# N32H7xx register map
Vendor: Nationstech Ltd.; File version: 1.0
CPU: CM7 r1p1, little endian, MPU, FPU, 4 interrupt priority bits
Registers are 32-bit, read-write, reset 0x0 unless marked. A register's access mark holds for its fields unless they carry their own. Offsets are from the block's base; [hi:lo] are bit positions; {n}, {i} and the like mark numbered series; 'fields as' and 'values as' point back to an identical list.

## RTC — Real time clock
Base 0x58005400
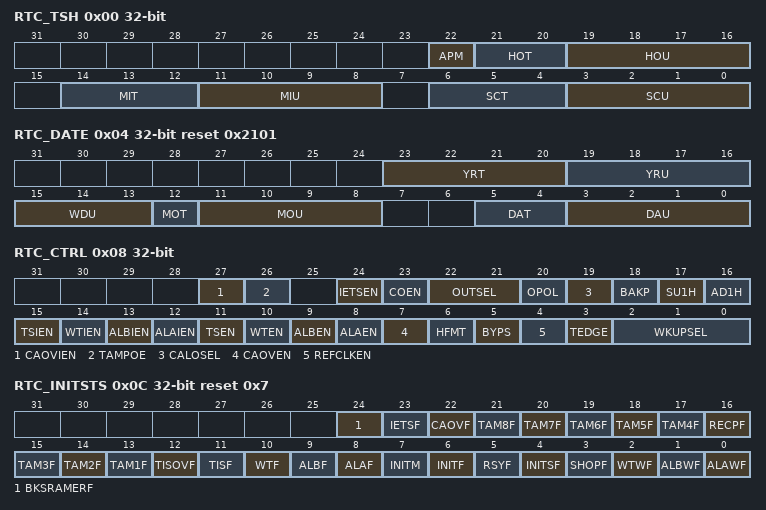
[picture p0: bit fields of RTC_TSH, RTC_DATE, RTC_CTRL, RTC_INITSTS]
0x00 RTC_TSH reset not defined
  [22] APM, [21:20] HOT, [19:16] HOU, [14:12] MIT, [11:8] MIU, [6:4] SCT, [3:0] SCU
0x04 RTC_DATE reset 0x2101
  [23:20] YRT, [19:16] YRU, [15:13] WDU, [12] MOT, [11:8] MOU, [5:4] DAT, [3:0] DAU
0x08 RTC_CTRL (reset mask 0xFFFFFF)
  [27] CAOVIEN, [26] TAMPOE, [24] IETSEN, [23] COEN, [22:21] OUTSEL, [20] OPOL, [19] CALOSEL, [18] BAKP, [17] SU1H wo, [16] AD1H wo, [15] TSIEN, [14] WTIEN, [13] ALBIEN, [12] ALAIEN, [11] TSEN, [10] WTEN, [9] ALBEN, [8] ALAEN, [7] CAOVEN, [6] HFMT, [5] BYPS, [4] REFCLKEN, [3] TEDGE, [2:0] WKUPSEL
0x0C RTC_INITSTS reset 0x7 (reset mask 0x17FFF)
  [24] BKSRAMERF ro, [23] IETSF, [22] CAOVF, [n+13] TAM{n}F (n=4..8), [16] RECPF ro, [15] TAM3F, [14] TAM2F, [13] TAM1F, [12] TISOVF, [11] TISF, [10] WTF, [9] ALBF, [8] ALAF, [7] INITM, [6] INITF ro, [5] RSYF, [4] INITSF ro, [3] SHOPF ro, [2] WTWF ro, [1] ALBWF ro, [0] ALAWF ro
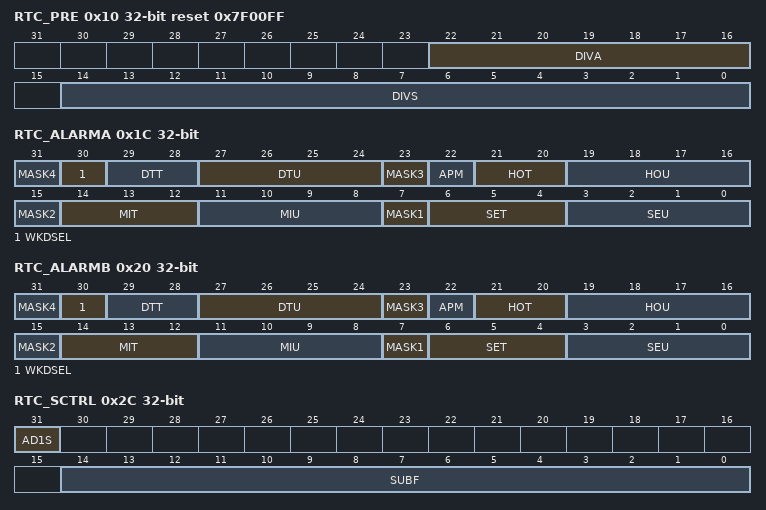
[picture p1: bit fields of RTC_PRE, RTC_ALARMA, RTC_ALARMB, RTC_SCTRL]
0x10 RTC_PRE reset 0x7F00FF
  [22:16] DIVA, [14:0] DIVS
0x14 RTC_WKUPT reset 0xFFFF
  [15:0] WKUPT
0x1C RTC_ALARMA
  [8n-1] MASK{n} (n=1..4), [30] WKDSEL, [29:28] DTT, [27:24] DTU, [22] APM, [21:20] HOT, [19:16] HOU, [14:12] MIT, [11:8] MIU, [6:4] SET, [3:0] SEU
0x20 RTC_ALARMB
  fields as RTC_ALARMA
0x24 RTC_WRP wo
  [7:0] PKEY
0x28 RTC_SUBS ro
  [15:0] SS
0x2C RTC_SCTRL wo
  [31] AD1S, [14:0] SUBF
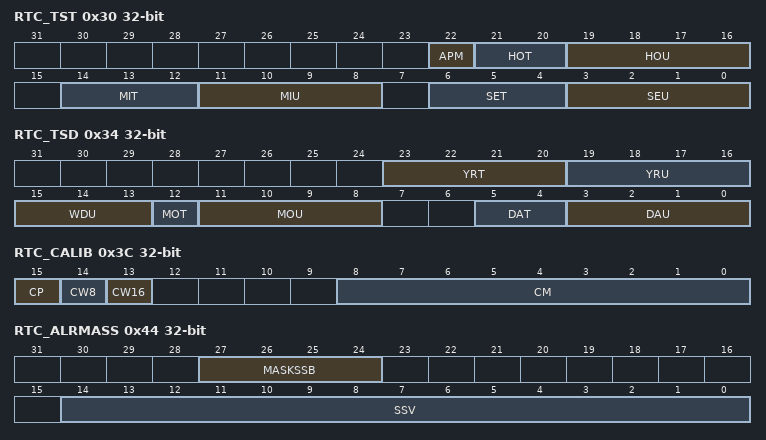
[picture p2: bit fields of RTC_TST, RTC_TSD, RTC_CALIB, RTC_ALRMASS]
0x30 RTC_TST ro (reset mask 0x7F)
  [22] APM, [21:20] HOT, [19:16] HOU, [14:12] MIT, [11:8] MIU, [6:4] SET, [3:0] SEU
0x34 RTC_TSD ro
  fields as RTC_DATE
0x38 RTC_TSSS ro
  [15:0] SSE
0x3C RTC_CALIB (reset mask 0xFF)
  [15] CP, [14] CW8, [13] CW16, [8:0] CM
0x44 RTC_ALRMASS
  [27:24] MASKSSB, [14:0] SSV
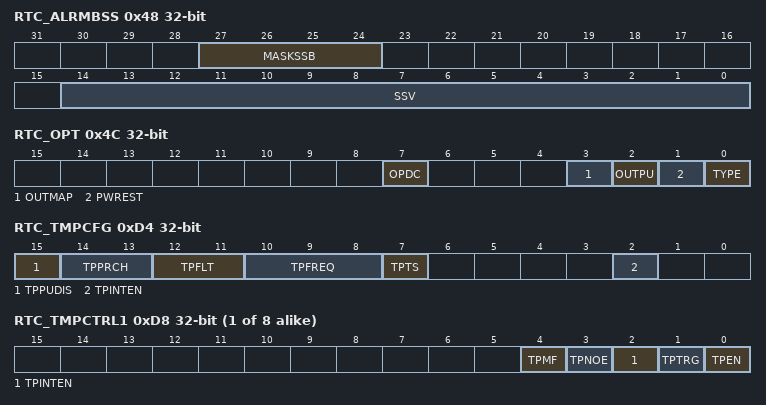
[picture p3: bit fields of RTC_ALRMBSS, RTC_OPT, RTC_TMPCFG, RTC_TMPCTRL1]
0x48 RTC_ALRMBSS
  [27:24] MASKSSB, [14:0] SSV
0x4C RTC_OPT (reset mask 0x1)
  [7] OPDC, [3] OUTMAP, [2] OUTPU, [1] PWREST, [0] TYPE
{0x4C+4i} RTC_BKP{i} (i=1..27)
  [31:0] BF
0xBC RTC_BKP28 — RTC_BKP27
  [31:0] BF
{0x4C+4i} RTC_BKP{i} (i=29..32)
  [31:0] BF
0xD4 RTC_TMPCFG
  [15] TPPUDIS, [14:13] TPPRCH, [12:11] TPFLT, [10:8] TPFREQ, [7] TPTS, [2] TPINTEN
{0xD4+4i} RTC_TMPCTRL{i} (i=1..8)
  [4] TPMF, [3] TPNOE, [2] TPINTEN, [1] TPTRG, [0] TPEN

## xSPI1 — Multi-line SPI
Base 0x51100000
Same registers: xSPI2 0x51101000
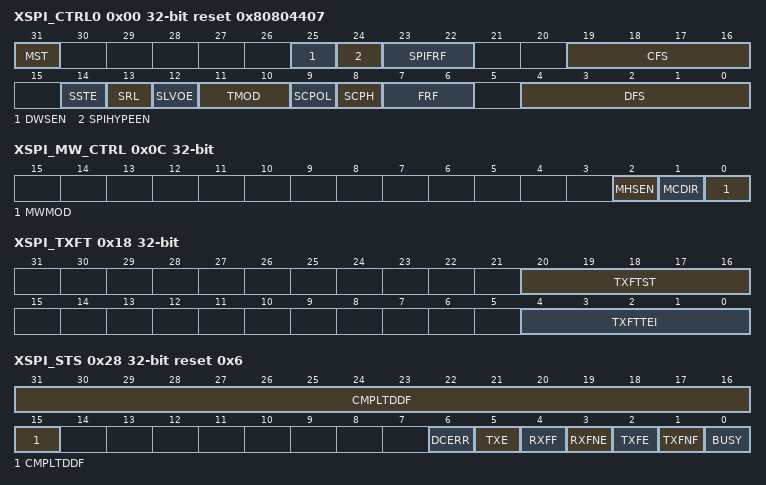
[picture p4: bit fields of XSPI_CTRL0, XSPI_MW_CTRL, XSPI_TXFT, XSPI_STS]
0x00 XSPI_CTRL0 reset 0x80804407
  [31] MST, [25] DWSEN ro, [24] SPIHYPEEN ro, [23:22] SPIFRF, [19:16] CFS, [14] SSTE, [13] SRL, [12] SLVOE, [11:10] TMOD, [9] SCPOL, [8] SCPH, [7:6] FRF, [4:0] DFS
0x04 XSPI_CTRL1
  [15:0] NDF
0x08 XSPI_EN
  [0] XSPIEN
0x0C XSPI_MW_CTRL
  [2] MHSEN, [1] MCDIR, [0] MWMOD
0x10 XSPI_SLAVE_EN reset 0x1
  [3:0] SEN
0x14 XSPI_BAUD
  [15:1] CLKDIV
0x18 XSPI_TXFT
  [20:16] TXFTST, [4:0] TXFTTEI
0x1C XSPI_RXFT
  [4:0] RXFTTFI
0x20 XSPI_TXFN ro
  [5:0] TXFN
0x24 XSPI_RXFN ro
  [5:0] RXFN
0x28 XSPI_STS ro reset 0x6
  [31:15] CMPLTDDF, [6] DCERR, [5] TXE, [4] RXFF, [3] RXFNE, [2] TXFE, [1] TXFNF, [0] BUSY
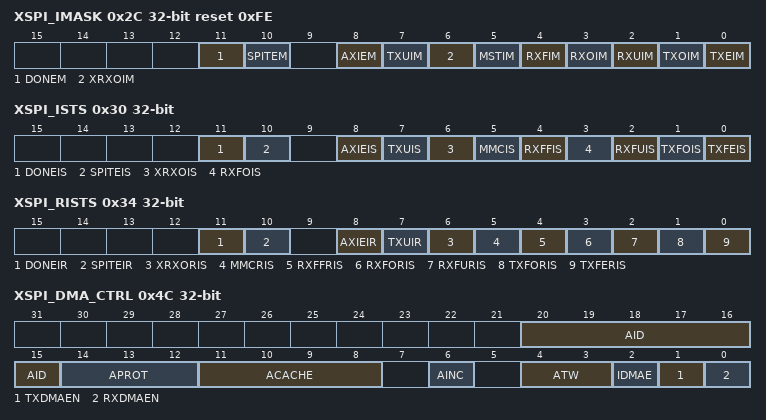
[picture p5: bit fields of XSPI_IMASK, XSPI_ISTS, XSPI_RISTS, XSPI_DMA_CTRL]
0x2C XSPI_IMASK reset 0xFE
  [11] DONEM ro, [10] SPITEM ro, [8] AXIEM ro, [7] TXUIM, [6] XRXOIM, [5] MSTIM, [4] RXFIM, [3] RXOIM, [2] RXUIM, [1] TXOIM, [0] TXEIM
0x30 XSPI_ISTS ro
  [11] DONEIS, [10] SPITEIS, [8] AXIEIS, [7] TXUIS, [6] XRXOIS, [5] MMCIS, [4] RXFFIS, [3] RXFOIS, [2] RXFUIS, [1] TXFOIS, [0] TXFEIS
0x34 XSPI_RISTS
  [11] DONEIR ro, [10] SPITEIR ro, [8] AXIEIR ro, [7] TXUIR ro, [6] XRXORIS ro, [5] MMCRIS ro, [4] RXFFRIS ro, [3] RXFORIS ro, [2] RXFURIS ro, [1] TXFORIS ro, [0] TXFERIS ro
0x38 XSPI_TXEICR_CLR ro
  [0] TXEICR
0x3C XSPI_RXFOI_CLR ro
  [0] RXFOIC
0x40 XSPI_RXFUI_CLR ro
  [0] RXFUIC
0x44 XSPI_MMC_CLR ro
  [0] MMCIC
0x48 XSPI_ICLR ro
  [0] INTC
0x4C XSPI_DMA_CTRL
  [20:15] AID ro, [14:12] APROT ro, [11:8] ACACHE ro, [6] AINC ro, [4:3] ATW ro, [2] IDMAE ro, [1] TXDMAEN, [0] RXDMAEN
0x50 XSPI_DMATDL_CTRL
  [4:0] DMATDL
0x54 XSPI_DMARDL_CTRL
  [4:0] DMARDL
0x58 XSPI_IDR ro reset 0xFFFF3610
  [31:0] IDCODE
0x5C XSPI_VERSION_ID ro reset 0x3130332A
  [31:0] VERSION
0x60 XSPI_DATx
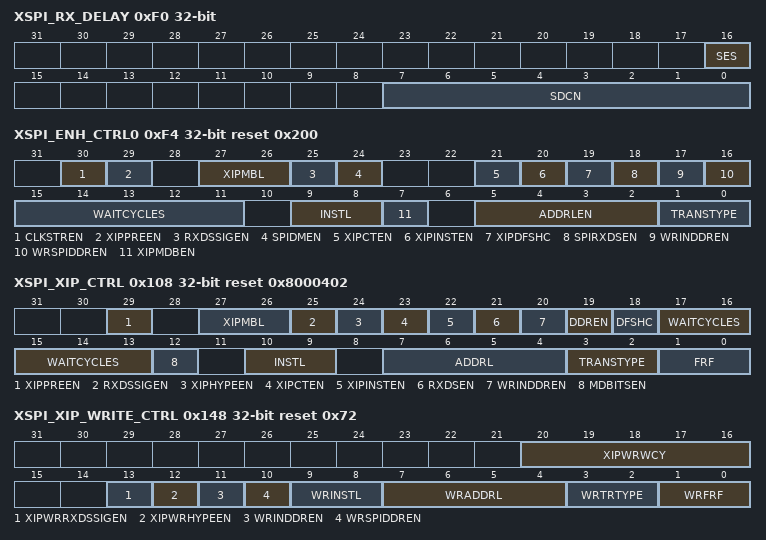
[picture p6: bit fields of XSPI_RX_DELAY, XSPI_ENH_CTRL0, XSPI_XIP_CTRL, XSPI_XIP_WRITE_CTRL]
0xF0 XSPI_RX_DELAY
  [16] SES, [7:0] SDCN
0xF4 XSPI_ENH_CTRL0 reset 0x200
  [30] CLKSTREN, [29] XIPPREEN ro, [27:26] XIPMBL ro, [25] RXDSSIGEN ro, [24] SPIDMEN, [21] XIPCTEN ro, [20] XIPINSTEN ro, [19] XIPDFSHC ro, [18] SPIRXDSEN, [17] WRINDDREN, [16] WRSPIDDREN, [15:11] WAITCYCLES, [9:8] INSTL, [7] XIPMDBEN ro, [5:2] ADDRLEN, [1:0] TRANSTYPE
0xF8 XSPI_DDR_TXDE
  [7:0] TXDE
0xFC XSPI_XIP_MODE
  [15:0] XIPMDBITS
0x100 XSPI_XIP_INCR_TOC
  [15:0] ITOC
0x104 XSPI_XIP_WRAP_TOC
  [15:0] WTOC
0x108 XSPI_XIP_CTRL reset 0x8000402
  [29] XIPPREEN, [27:26] XIPMBL, [25] RXDSSIGEN ro, [24] XIPHYPEEN ro, [23] XIPCTEN, [22] XIPINSTEN, [21] RXDSEN, [20] WRINDDREN, [19] DDREN, [18] DFSHC, [17:13] WAITCYCLES, [12] MDBITSEN, [10:9] INSTL, [7:4] ADDRL, [3:2] TRANSTYPE, [1:0] FRF
0x10C XSPI_XIP_SLAVE_EN
  [3:0] SEN
0x110 XSPI_XIP_RXFOI_CLR ro
  [0] XRXFOIC
0x114 XSPI_XIP_TOUT
  [7:0] XTOUT
0x140 XSPI_XIP_WRITE_INCR_INST
  [15:0] INCRWRINST
0x144 XSPI_XIP_WRITE_WRAP_INST
  [15:0] WRAPWRINST
0x148 XSPI_XIP_WRITE_CTRL reset 0x72
  [20:16] XIPWRWCY ro, [13] XIPWRRXDSSIGEN ro, [12] XIPWRHYPEEN ro, [11] WRINDDREN, [10] WRSPIDDREN, [9:8] WRINSTL, [7:4] WRADDRL, [3:2] WRTRTYPE, [1:0] WRFRF
0x180 XSPI_XIP_WRITE_TIMING
  [31:0] TPP
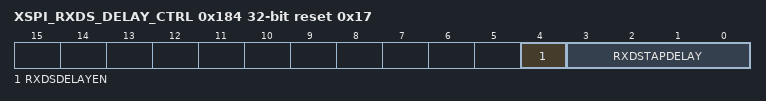
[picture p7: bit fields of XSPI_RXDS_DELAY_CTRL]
0x184 XSPI_RXDS_DELAY_CTRL reset 0x17
  [4] RXDSDELAYEN, [3:0] RXDSTAPDELAY
